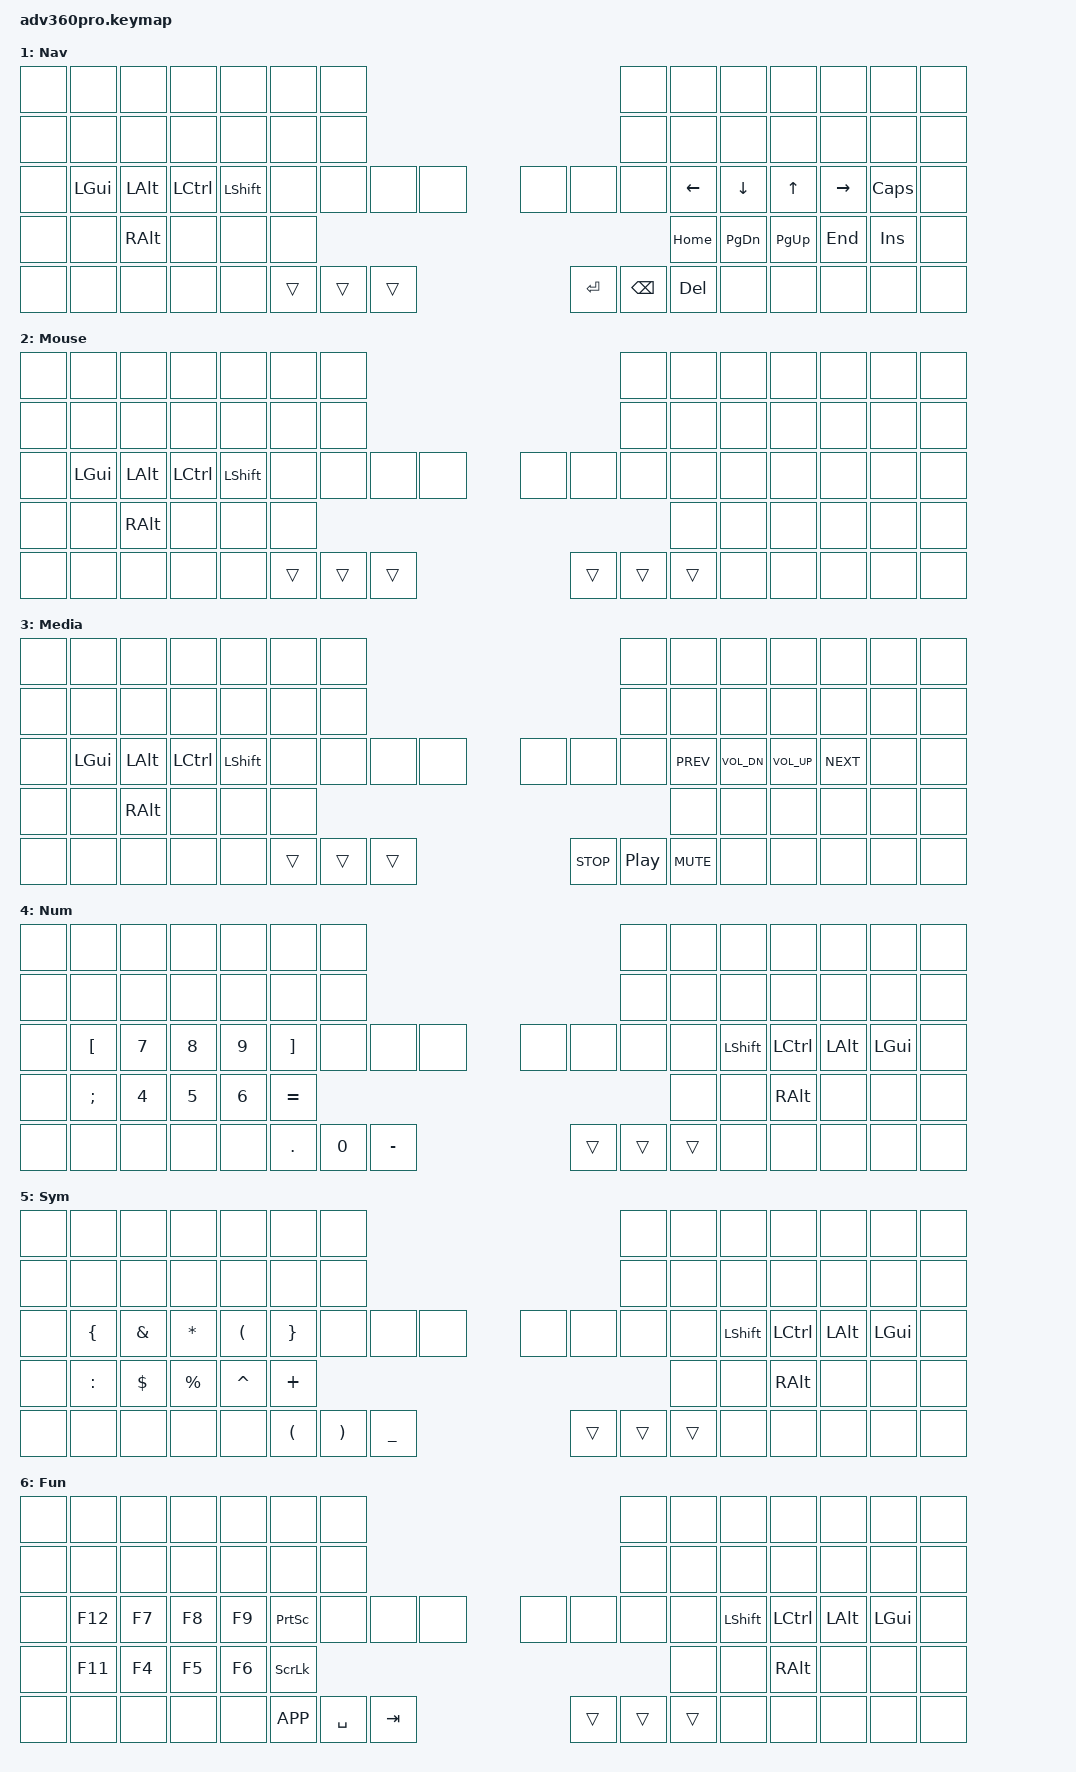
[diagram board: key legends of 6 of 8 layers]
// Static Miryoku layout for Kinesis Advantage 360 Pro
// This is a hardcoded Miryoku-style layout that works with mainline ZMK
// Compatible with physical layout system and ZMK Studio

#include <behaviors.dtsi>
#include <dt-bindings/zmk/keys.h>
#include <dt-bindings/zmk/bt.h>
#include <dt-bindings/zmk/outputs.h>

// Miryoku-style home row mods
&mt {
    flavor = "balanced";
    tapping-term-ms = <200>;
    quick-tap-ms = <175>;
    require-prior-idle-ms = <150>;
};

&lt {
    flavor = "balanced";
    tapping-term-ms = <200>;
    quick-tap-ms = <175>;
    require-prior-idle-ms = <150>;
};

/ {
    behaviors {
        // Home row mods compatible behavior
        hml: homerow_mods_left {
            compatible = "zmk,behavior-hold-tap";
            #binding-cells = <2>;
            flavor = "balanced";
            tapping-term-ms = <280>;
            quick-tap-ms = <175>;
            require-prior-idle-ms = <150>;
            bindings = <&kp>, <&kp>;
            hold-trigger-key-positions = <5 6 7 8 9 10 11 12 13  // right hand
                                           21 22 23 24 25 26 27
                                           39 40 41 42 43 44 45
                                           54 55 56 57 58 59     // right thumbs
                                           71 72 73 74 75>;       // right bottom row
            hold-trigger-on-release;
        };

        hmr: homerow_mods_right {
            compatible = "zmk,behavior-hold-tap";
            #binding-cells = <2>;
            flavor = "balanced";
            tapping-term-ms = <280>;
            quick-tap-ms = <175>;
            require-prior-idle-ms = <150>;
            bindings = <&kp>, <&kp>;
            hold-trigger-key-positions = <0 1 2 3 4 5 6  // left hand
                                           14 15 16 17 18 19 20
                                           28 29 30 31 32 33 34
                                           46 47 48 49 50 51     // left thumbs
                                           60 61 62 63 64>;       // left bottom row
            hold-trigger-on-release;
        };
    };

    keymap {
        compatible = "zmk,keymap";

        // Base layer - Colemak-DH with home row mods
        base_layer {
            display-name = "Base";
            bindings = <
                // Row 1 (top function row)
                &none &none &none &none &none &none &none                                                           &none &none &none &none &none &none &none
                // Row 2 (number row)
                &none &kp Q     &kp W      &kp F       &kp P       &kp B      &none                                                           &none &kp J      &kp L       &kp U       &kp Y      &kp SQT    &none
                // Row 3 (home row with mods)
                &none &hml LGUI A &hml LALT R &hml LCTRL S &hml LSHFT T &kp G      &none           &none &none                 &none &none   &none &kp M      &hmr LSHFT N &hmr LCTRL E &hmr LALT I &hmr LGUI O &none
                // Row 4 (bottom letter row) - 14 keys
                &none &kp Z &kp X &kp C &kp D &kp V &none &none &kp K &kp H &kp COMMA &kp DOT &kp SLASH &none
                // Row 5 (thumb cluster and bottom row)
                &none &none     &none      &none       &none                      &lt 3 ESC &lt 1 SPACE &lt 2 TAB     &lt 4 RET &lt 5 BSPC &lt 6 DEL                &none       &none      &none      &none      &none
            >;
        };

        // Layer 1 - Nav
        nav_layer {
            display-name = "Nav";
            bindings = <
                &none &none &none &none &none &none &none                                                           &none &none &none &none &none &none &none
                &none &none &none &none &none &none &none                                                           &none &none &none &none &none &none &none
                &none &kp LGUI &kp LALT &kp LCTRL &kp LSHFT &none &none           &none &none                 &none &none   &none &kp LEFT &kp DOWN &kp UP &kp RIGHT &kp CAPS &none
                &none &none &kp RALT &none &none &none                            &kp HOME &kp PG_DN &kp PG_UP &kp END &kp INS &none
                &none &none &none &none &none                      &trans &trans &trans     &kp RET &kp BSPC &kp DEL                &none &none &none &none &none
            >;
        };

        // Layer 2 - Mouse
        mouse_layer {
            display-name = "Mouse";
            bindings = <
                &none &none &none &none &none &none &none                                                           &none &none &none &none &none &none &none
                &none &none &none &none &none &none &none                                                           &none &none &none &none &none &none &none
                &none &kp LGUI &kp LALT &kp LCTRL &kp LSHFT &none &none           &none &none                 &none &none   &none &none &none &none &none &none &none
                &none &none &kp RALT &none &none &none                            &none &none &none &none &none &none
                &none &none &none &none &none                      &trans &trans &trans     &trans &trans &trans                &none &none &none &none &none
            >;
        };

        // Layer 3 - Media
        media_layer {
            display-name = "Media";
            bindings = <
                &none &none &none &none &none &none &none                                                           &none &none &none &none &none &none &none
                &none &none &none &none &none &none &none                                                           &none &none &none &none &none &none &none
                &none &kp LGUI &kp LALT &kp LCTRL &kp LSHFT &none &none           &none &none                 &none &none   &none &kp C_PREV &kp C_VOL_DN &kp C_VOL_UP &kp C_NEXT &none &none
                &none &none &kp RALT &none &none &none                            &none &none &none &none &none &none
                &none &none &none &none &none                      &trans &trans &trans     &kp C_STOP &kp C_PP &kp C_MUTE                &none &none &none &none &none
            >;
        };

        // Layer 4 - Num
        num_layer {
            display-name = "Num";
            bindings = <
                &none &none &none &none &none &none &none                                                           &none &none &none &none &none &none &none
                &none &none &none &none &none &none &none                                                           &none &none &none &none &none &none &none
                &none &kp LBKT &kp N7 &kp N8 &kp N9 &kp RBKT &none           &none &none                 &none &none   &none &none &kp LSHFT &kp LCTRL &kp LALT &kp LGUI &none
                &none &kp SEMI &kp N4 &kp N5 &kp N6 &kp EQUAL                      &none &none &kp RALT &none &none &none
                &none &none &none &none &none                      &kp DOT &kp N0 &kp MINUS     &trans &trans &trans                &none &none &none &none &none
            >;
        };

        // Layer 5 - Sym
        sym_layer {
            display-name = "Sym";
            bindings = <
                &none &none &none &none &none &none &none                                                           &none &none &none &none &none &none &none
                &none &none &none &none &none &none &none                                                           &none &none &none &none &none &none &none
                &none &kp LBRC &kp AMPS &kp ASTRK &kp LPAR &kp RBRC &none           &none &none                 &none &none   &none &none &kp LSHFT &kp LCTRL &kp LALT &kp LGUI &none
                &none &kp COLON &kp DLLR &kp PRCNT &kp CARET &kp PLUS                      &none &none &kp RALT &none &none &none
                &none &none &none &none &none                      &kp LPAR &kp RPAR &kp UNDER     &trans &trans &trans                &none &none &none &none &none
            >;
        };

        // Layer 6 - Fun
        fun_layer {
            display-name = "Fun";
            bindings = <
                &none &none &none &none &none &none &none                                                           &none &none &none &none &none &none &none
                &none &none &none &none &none &none &none                                                           &none &none &none &none &none &none &none
                &none &kp F12 &kp F7 &kp F8 &kp F9 &kp PSCRN &none           &none &none                 &none &none   &none &none &kp LSHFT &kp LCTRL &kp LALT &kp LGUI &none
                &none &kp F11 &kp F4 &kp F5 &kp F6 &kp SLCK                        &none &none &kp RALT &none &none &none
                &none &none &none &none &none                      &kp K_APP &kp SPACE &kp TAB     &trans &trans &trans                &none &none &none &none &none
            >;
        };

        // Layer 7 - Button/System
        button_layer {
            display-name = "Sys";
            bindings = <
                &none &none &none &none &none &none &none                                                           &none &none &none &none &none &none &none
                &none &none &none &none &none &none &bootloader                                                     &bootloader &none &none &none &none &none &none
                &none &none &none &none &none &none &none           &none &none                 &bt BT_CLR &none   &none &none &none &none &none &none &none
                &none &none &none &none &none &none                        &none &none                 &none &none         &bt BT_SEL 0 &bt BT_SEL 1 &bt BT_SEL 2 &bt BT_SEL 3 &out OUT_TOG &none
                &none &none &none &none &none                      &none &none &none     &none &none &none                &none &none &none &none &none
            >;
        };
    };
};
